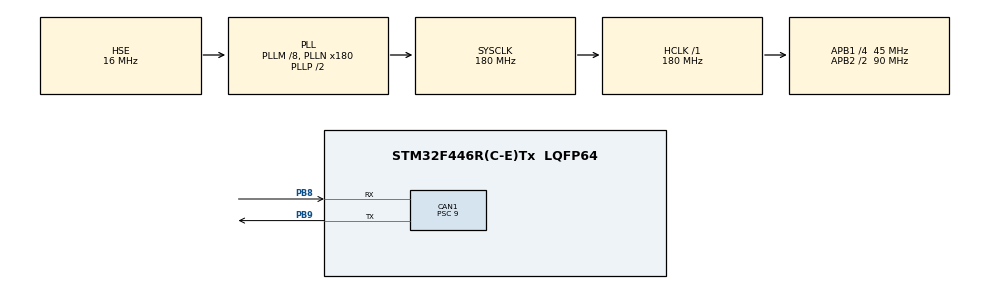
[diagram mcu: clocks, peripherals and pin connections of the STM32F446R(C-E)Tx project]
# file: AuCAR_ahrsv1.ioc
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CAN1.ABOM=DISABLE
CAN1.AWUM=DISABLE
CAN1.BS1=CAN_BS1_3TQ
CAN1.CalculateTimeQuantum=200.0
CAN1.Mode=CAN_MODE_NORMAL
CAN1.NART=ENABLE
CAN1.Prescaler=9
CAN1.SJW=CAN_SJW_1TQ
Mcu.Family=STM32F4
Mcu.Name=STM32F446R(C-E)Tx
Mcu.Package=LQFP64
NVIC.CAN1_RX0_IRQn=true\:0\:0\:false\:false\:true\:true\:true
NVIC.CAN1_RX1_IRQn=true\:0\:0\:false\:false\:true\:true\:true
NVIC.CAN1_SCE_IRQn=true\:0\:0\:false\:false\:true\:true\:true
NVIC.CAN1_TX_IRQn=true\:0\:0\:false\:false\:true\:true\:true
NVIC.PriorityGroup=NVIC_PRIORITYGROUP_4
NVIC.RCC_IRQn=true\:0\:0\:false\:false\:true\:true\:false
PA13.Mode=Serial_Wire
PA13.Signal=SYS_JTMS-SWDIO
PA14.Mode=Serial_Wire
PA14.Signal=SYS_JTCK-SWCLK
PB8.Mode=Master
PB8.Signal=CAN1_RX
PB9.Mode=Master
PB9.Signal=CAN1_TX
PH0-OSC_IN.Mode=HSE-External-Oscillator
PH0-OSC_IN.Signal=RCC_OSC_IN
PH1-OSC_OUT.Mode=HSE-External-Oscillator
PH1-OSC_OUT.Signal=RCC_OSC_OUT
ProjectManager.HeapSize=0x200
ProjectManager.StackSize=0x400
ProjectManager.TargetToolchain=STM32CubeIDE
RCC.AHBFreq_Value=180000000
RCC.APB1CLKDivider=RCC_HCLK_DIV4
RCC.APB1Freq_Value=45000000
RCC.APB1TimFreq_Value=90000000
RCC.APB2CLKDivider=RCC_HCLK_DIV2
RCC.APB2Freq_Value=90000000
RCC.APB2TimFreq_Value=180000000
RCC.CortexFreq_Value=180000000
RCC.HCLKFreq_Value=180000000
RCC.HSE_VALUE=16000000
RCC.PLLM=8
RCC.PLLN=180
RCC.PLLSourceVirtual=RCC_PLLSOURCE_HSE
RCC.SYSCLKFreq_VALUE=180000000
RCC.SYSCLKSource=RCC_SYSCLKSOURCE_PLLCLK
RCC.USBFreq_Value=180000000
RCC.VCOOutputFreq_Value=360000000
board=custom

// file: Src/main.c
/* USER CODE BEGIN Header */
/**
 ******************************************************************************
 * @file           : main.c
 * @brief          : Main program body
 ******************************************************************************
 * @attention
 *
 * <h2><center>&copy; Copyright (c) 2020 STMicroelectronics.
 * All rights reserved.</center></h2>
 *
 * This software component is licensed by ST under BSD 3-Clause license,
 * the "License"; You may not use this file except in compliance with the
 * License. You may obtain a copy of the License at:
 *                        opensource.org/licenses/BSD-3-Clause
 *
 ******************************************************************************
 */
/* USER CODE END Header */

#include "main.h"
#include "can.h"
#include "gpio.h"

/* USER CODE BEGIN Includes */
#include "MW-AHRSv1.h"
/* USER CODE END Includes */

/* USER CODE BEGIN PTD */
void mw_ahrsv1_init(void);
void mw_trans_init(void);
/* USER CODE END PTD */

/* USER CODE BEGIN PV */
extern CAN_HandleTypeDef hcan1;
CAN_TxHeaderTypeDef can_tx_hedder = { 0, };
CAN_RxHeaderTypeDef can_rx_hedder = { 0, };
uint8_t can_tx_data[8] = { 0, };
uint8_t can_rx_data[8] = { 0, };
MW_AHRS ahrs_obj;
/* USER CODE END PV */

void SystemClock_Config(void);

int main(void)
{

  /* MCU Configuration--------------------------------------------------------*/

  /* Reset of all peripherals, Initializes the Flash interface and the Systick. */
  HAL_Init();

  /* Configure the system clock */
  SystemClock_Config();

  /* Initialize all configured peripherals */
  MX_GPIO_Init();
  MX_CAN1_Init();
  /* USER CODE BEGIN 2 */

	uint32_t nowTick = 0;
	uint32_t pastTick = 0;
	mw_ahrsv1_init();

	HAL_CAN_ActivateNotification(&hcan1,
			CAN_IT_TX_MAILBOX_EMPTY | CAN_IT_RX_FIFO0_MSG_PENDING | CAN_IT_RX_FIFO0_FULL);
	HAL_CAN_Start(&hcan1);

	mw_trans_init();

  /* USER CODE END 2 */

  /* Infinite loop */
	while (1) {

    /* USER CODE BEGIN 3 */
		nowTick = HAL_GetTick();
		if (nowTick - pastTick > 1000)
		{
			//mw_trans_init();
			//mw_trans_init();
			//mw_trans_init();
			pastTick = nowTick;
		}
	}
  /* USER CODE END 3 */
}

void SystemClock_Config(void)
{
  RCC_OscInitTypeDef RCC_OscInitStruct = {0};
  RCC_ClkInitTypeDef RCC_ClkInitStruct = {0};

  /** Configure the main internal regulator output voltage
  */
  __HAL_RCC_PWR_CLK_ENABLE();
  __HAL_PWR_VOLTAGESCALING_CONFIG(PWR_REGULATOR_VOLTAGE_SCALE1);
  /** Initializes the CPU, AHB and APB busses clocks
  */
  RCC_OscInitStruct.OscillatorType = RCC_OSCILLATORTYPE_HSE;
  RCC_OscInitStruct.HSEState = RCC_HSE_ON;
  RCC_OscInitStruct.PLL.PLLState = RCC_PLL_ON;
  RCC_OscInitStruct.PLL.PLLSource = RCC_PLLSOURCE_HSE;
  RCC_OscInitStruct.PLL.PLLM = 8;
  RCC_OscInitStruct.PLL.PLLN = 180;
  RCC_OscInitStruct.PLL.PLLP = RCC_PLLP_DIV2;
  RCC_OscInitStruct.PLL.PLLQ = 2;
  RCC_OscInitStruct.PLL.PLLR = 2;
  if (HAL_RCC_OscConfig(&RCC_OscInitStruct) != HAL_OK)
  {
    Error_Handler();
  }
  /** Activate the Over-Drive mode
  */
  if (HAL_PWREx_EnableOverDrive() != HAL_OK)
  {
    Error_Handler();
  }
  /** Initializes the CPU, AHB and APB busses clocks
  */
  RCC_ClkInitStruct.ClockType = RCC_CLOCKTYPE_HCLK|RCC_CLOCKTYPE_SYSCLK
                              |RCC_CLOCKTYPE_PCLK1|RCC_CLOCKTYPE_PCLK2;
  RCC_ClkInitStruct.SYSCLKSource = RCC_SYSCLKSOURCE_PLLCLK;
  RCC_ClkInitStruct.AHBCLKDivider = RCC_SYSCLK_DIV1;
  RCC_ClkInitStruct.APB1CLKDivider = RCC_HCLK_DIV4;
  RCC_ClkInitStruct.APB2CLKDivider = RCC_HCLK_DIV2;

  if (HAL_RCC_ClockConfig(&RCC_ClkInitStruct, FLASH_LATENCY_5) != HAL_OK)
  {
    Error_Handler();
  }
}

/* USER CODE BEGIN 4 */

uint32_t canTxMailBox;
void mw_ahrsv1_init(void) {

	CAN_FilterTypeDef canFilter;
	canFilter.FilterFIFOAssignment = CAN_FILTER_FIFO0;
	canFilter.FilterMode = CAN_FILTERMODE_IDMASK;
	canFilter.FilterScale = CAN_FILTERSCALE_32BIT;
	canFilter.FilterIdHigh = 0x0000 << 5;
	canFilter.FilterIdLow = 0x0000;
	canFilter.FilterMaskIdHigh = 0x0000 << 5;
	canFilter.FilterMaskIdLow = 0x0000;
	canFilter.SlaveStartFilterBank = 0;
	canFilter.FilterBank = 0;
	canFilter.FilterActivation = CAN_FILTER_ENABLE;

	if(HAL_CAN_ConfigFilter(&hcan1, &canFilter) != HAL_OK)
	{
		Error_Handler();
	}
}

void mw_trans_init(void)
{
	can_tx_hedder.StdId = 0x01;
	can_tx_hedder.ExtId = 0x01;
	can_tx_hedder.RTR = CAN_RTR_DATA;
	can_tx_hedder.IDE = CAN_ID_STD;
	can_tx_hedder.DLC = 8;

	mw_ahrs_set_period(&ahrs_obj, 1);
	mw_ahrs_set_data_type(&ahrs_obj, 1, 1, 1, 1);
	for(int i=0; i<8; i++)
	{
	can_tx_data[i] = ahrs_obj.can_write_data[i];
	}
	if (HAL_CAN_AddTxMessage(&hcan1, &can_tx_hedder, can_tx_data, &canTxMailBox)
			!= HAL_OK) {
		Error_Handler();
	}
}

uint32_t canTxCallback = 0;
uint32_t canRxCallback = 0;
uint32_t canRxFullCallback = 0;
uint32_t canErrorCallback = 0;
void HAL_CAN_TxMailbox0CompleteCallback(CAN_HandleTypeDef *hcan) {
	if (hcan->Instance == CAN1) {
		canTxCallback++;
	}
}

void HAL_CAN_RxFifo0MsgPendingCallback(CAN_HandleTypeDef *hcan) {
	if (hcan->Instance == CAN1) {
		canRxCallback++;
		HAL_CAN_GetRxMessage(&hcan1, CAN_RX_FIFO0, &can_rx_hedder, can_rx_data);
		for (int i = 0; i < 8; i++) {
			ahrs_obj.can_read_data[i] = can_rx_data[i];
		}
		mw_ahrs_input_data(&ahrs_obj);

	}
}
void HAL_CAN_RxFifo0FullCallback(CAN_HandleTypeDef *hcan) {
	if (hcan->Instance == CAN1) {
		canRxFullCallback++;
	}
}

void HAL_CAN_ErrorCallback(CAN_HandleTypeDef *hcan)
{

	if(hcan->Instance == CAN1)
	{
		canErrorCallback++;
	}
}
/* USER CODE END 4 */

void Error_Handler(void)
{
}

/************************ (C) COPYRIGHT STMicroelectronics *****END OF FILE****/
